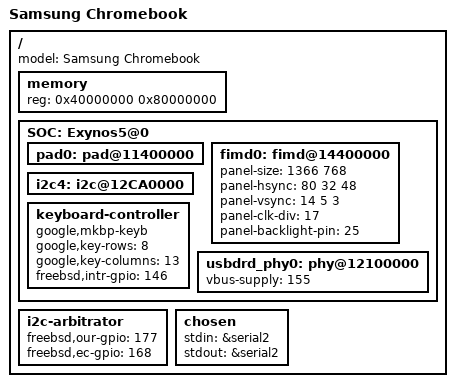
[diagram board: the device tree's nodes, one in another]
/*-
 * Copyright (c) 2014 Ruslan Bukin <br@bsdpad.com>
 * All rights reserved.
 *
 * Redistribution and use in source and binary forms, with or without
 * modification, are permitted provided that the following conditions
 * are met:
 * 1. Redistributions of source code must retain the above copyright
 *    notice, this list of conditions and the following disclaimer.
 * 2. Redistributions in binary form must reproduce the above copyright
 *    notice, this list of conditions and the following disclaimer in the
 *    documentation and/or other materials provided with the distribution.
 *
 * THIS SOFTWARE IS PROVIDED BY THE AUTHOR AND CONTRIBUTORS ``AS IS'' AND
 * ANY EXPRESS OR IMPLIED WARRANTIES, INCLUDING, BUT NOT LIMITED TO, THE
 * IMPLIED WARRANTIES OF MERCHANTABILITY AND FITNESS FOR A PARTICULAR PURPOSE
 * ARE DISCLAIMED. IN NO EVENT SHALL THE AUTHOR OR CONTRIBUTORS BE LIABLE
 * FOR ANY DIRECT, INDIRECT, INCIDENTAL, SPECIAL, EXEMPLARY, OR CONSEQUENTIAL
 * DAMAGES (INCLUDING, BUT NOT LIMITED TO, PROCUREMENT OF SUBSTITUTE GOODS
 * OR SERVICES; LOSS OF USE, DATA, OR PROFITS; OR BUSINESS INTERRUPTION)
 * HOWEVER CAUSED AND ON ANY THEORY OF LIABILITY, WHETHER IN CONTRACT, STRICT
 * LIABILITY, OR TORT (INCLUDING NEGLIGENCE OR OTHERWISE) ARISING IN ANY WAY
 * OUT OF THE USE OF THIS SOFTWARE, EVEN IF ADVISED OF THE POSSIBILITY OF
 * SUCH DAMAGE.
 *
 * $FreeBSD$
 */

/dts-v1/;

/include/ "exynos5250.dtsi"

/ {
	model = "Samsung Chromebook";

	memory {
		device_type = "memory";
		reg = < 0x40000000 0x80000000 >;  /* 2G */
	};

	SOC: Exynos5@0 {

		pad0: pad@11400000 {
			status = "okay";
		};

		fimd0: fimd@14400000 {
			status = "okay";

			panel-size = < 1366 768 >;
			panel-hsync = < 80 32 48 >;
			panel-vsync = < 14 5 3 >;
			panel-clk-div = < 17 >;
			panel-backlight-pin = < 25 >;
		};

		i2c4: i2c@12CA0000 {
			status = "okay";
		};

		keyboard-controller {
			compatible = "google,mkbp-keyb";
			google,key-rows = <8>;
			google,key-columns = <13>;
			freebsd,intr-gpio = <146>;
		};

		usbdrd_phy0: phy@12100000 {
			vbus-supply = < 155 >;
		};
	};

	i2c-arbitrator {
		freebsd,our-gpio = <177>;
		freebsd,ec-gpio = <168>;
	};

	chosen {
		stdin = &serial2;
		stdout = &serial2;
	};
};
